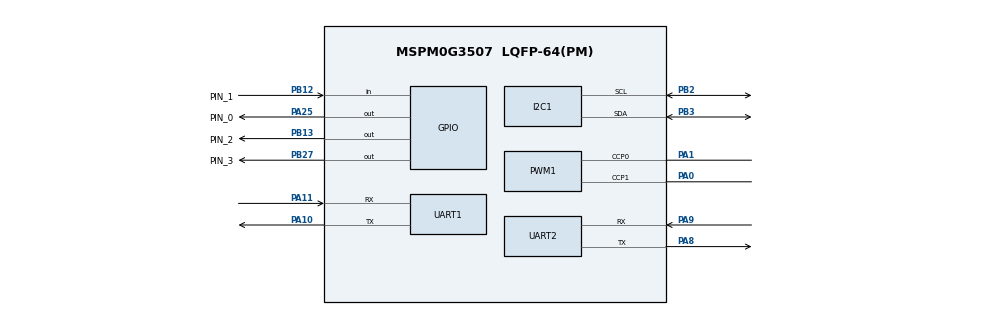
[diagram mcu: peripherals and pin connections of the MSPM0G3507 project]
/**
 * These arguments were used when this file was generated. They will be automatically applied on subsequent loads
 * via the GUI or CLI. Run CLI with '--help' for additional information on how to override these arguments.
 * @cliArgs --device "MSPM0G350X" --part "Default" --package "LQFP-64(PM)" --product "mspm0_sdk@2.07.00.06"
 * @v2CliArgs --device "MSPM0G3507" --package "LQFP-64(PM)" --product "mspm0_sdk@2.07.00.06"
 * @versions {"tool":"1.25.0+4268"}
 */

/**
 * Import the modules used in this configuration.
 */
const ADC12  = scripting.addModule("/ti/driverlib/ADC12", {}, false);
const ADC121 = ADC12.addInstance();
const GPIO   = scripting.addModule("/ti/driverlib/GPIO", {}, false);
const GPIO1  = GPIO.addInstance();
const GPIO2  = GPIO.addInstance();
const GPIO3  = GPIO.addInstance();
const GPIO4  = GPIO.addInstance();
const I2C    = scripting.addModule("/ti/driverlib/I2C", {}, false);
const I2C1   = I2C.addInstance();
const PWM    = scripting.addModule("/ti/driverlib/PWM", {}, false);
const PWM1   = PWM.addInstance();
const SYSCTL = scripting.addModule("/ti/driverlib/SYSCTL");
const UART   = scripting.addModule("/ti/driverlib/UART", {}, false);
const UART1  = UART.addInstance();
const UART2  = UART.addInstance();

/**
 * Write custom configuration values to the imported modules.
 */
ADC121.$name                      = "ADC12_0";
ADC121.enabledInterrupts          = ["DL_ADC12_INTERRUPT_DMA_DONE","DL_ADC12_INTERRUPT_MEM0_RESULT_LOADED","DL_ADC12_INTERRUPT_OVERFLOW","DL_ADC12_INTERRUPT_TRIG_OVF","DL_ADC12_INTERRUPT_UNDERFLOW"];
ADC121.adcPin0Config.$name        = "ti_driverlib_gpio_GPIOPinGeneric0";
ADC121.adcPin0Config.enableConfig = true;

const Board = scripting.addModule("/ti/driverlib/Board", {}, false);

GPIO1.$name                          = "MRDY";
GPIO1.associatedPins[0].$name        = "PIN_0";
GPIO1.associatedPins[0].initialValue = "SET";
GPIO1.associatedPins[0].pin.$assign  = "PA25";

GPIO2.$name                         = "SRDY";
GPIO2.associatedPins[0].$name       = "PIN_1";
GPIO2.associatedPins[0].direction   = "INPUT";
GPIO2.associatedPins[0].pin.$assign = "PB12";

GPIO3.$name                          = "RST";
GPIO3.associatedPins[0].$name        = "PIN_2";
GPIO3.associatedPins[0].initialValue = "SET";
GPIO3.associatedPins[0].pin.$assign  = "PB13";

GPIO4.$name                         = "LED";
GPIO4.associatedPins[0].$name       = "PIN_3";
GPIO4.associatedPins[0].pin.$assign = "PB27";

I2C1.$name                           = "I2C_0";
I2C1.basicEnableController           = true;
I2C1.basicControllerStandardBusSpeed = "Fast";
I2C1.peripheral.$assign              = "I2C1";
I2C1.peripheral.sdaPin.$assign       = "PB3";
I2C1.peripheral.sclPin.$assign       = "PB2";
I2C1.sdaPinConfig.$name              = "ti_driverlib_gpio_GPIOPinGeneric7";
I2C1.sclPinConfig.$name              = "ti_driverlib_gpio_GPIOPinGeneric8";

PWM1.$name                      = "PWM_0";
PWM1.peripheral.$assign         = "TIMG8";
PWM1.peripheral.ccp0Pin.$assign = "PA1";
PWM1.peripheral.ccp1Pin.$assign = "PA0";
PWM1.PWM_CHANNEL_0.$name        = "ti_driverlib_pwm_PWMTimerCC0";
PWM1.PWM_CHANNEL_1.$name        = "ti_driverlib_pwm_PWMTimerCC1";
PWM1.ccp0PinConfig.$name        = "ti_driverlib_gpio_GPIOPinGeneric5";
PWM1.ccp1PinConfig.$name        = "ti_driverlib_gpio_GPIOPinGeneric6";

SYSCTL.forceDefaultClkConfig = true;
SYSCTL.clockTreeEn           = true;

UART1.$name                    = "UART_0";
UART1.targetBaudRate           = 115200;
UART1.peripheral.rxPin.$assign = "PA11";
UART1.peripheral.txPin.$assign = "PA10";
UART1.txPinConfig.$name        = "ti_driverlib_gpio_GPIOPinGeneric1";
UART1.rxPinConfig.$name        = "ti_driverlib_gpio_GPIOPinGeneric2";

UART2.$name                    = "UART_1";
UART2.targetBaudRate           = 115200;
UART2.peripheral.$assign       = "UART1";
UART2.peripheral.rxPin.$assign = "PA9";
UART2.peripheral.txPin.$assign = "PA8";
UART2.txPinConfig.$name        = "ti_driverlib_gpio_GPIOPinGeneric3";
UART2.rxPinConfig.$name        = "ti_driverlib_gpio_GPIOPinGeneric4";

/**
 * Pinmux solution for unlocked pins/peripherals. This ensures that minor changes to the automatic solver in a future
 * version of the tool will not impact the pinmux you originally saw.  These lines can be completely deleted in order to
 * re-solve from scratch.
 */
ADC121.peripheral.$suggestSolution         = "ADC1";
ADC121.peripheral.adcPin0.$suggestSolution = "PA15";
Board.peripheral.$suggestSolution          = "DEBUGSS";
Board.peripheral.swclkPin.$suggestSolution = "PA20";
Board.peripheral.swdioPin.$suggestSolution = "PA19";
UART1.peripheral.$suggestSolution          = "UART0";
